# RL6955_IP_SVD register map
Vendor: Realtek
Registers are 32-bit, read-write, reset 0x0 unless marked. A register's access mark holds for its fields unless they carry their own. Offsets are from the block's base; [hi:lo] are bit positions; lines under a group give offsets from that group; {n}, {i} and the like mark numbered series.

## WMAC_PAGE17
Base 0x40000000
0x1700 REG_TWT_BC_ID
  [31:0] BC_TWT_ID — twt id bitmap, each bit corresponding to a ID value, only latch the report of valid twt id
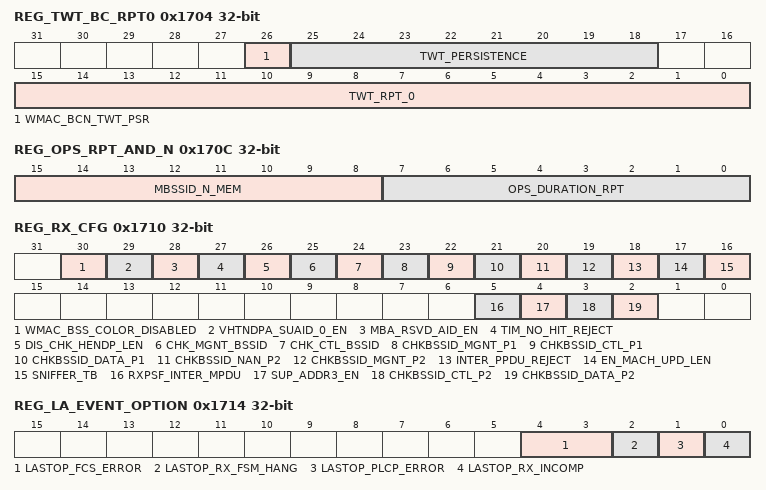
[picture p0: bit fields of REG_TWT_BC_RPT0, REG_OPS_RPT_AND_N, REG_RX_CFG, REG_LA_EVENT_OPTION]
0x1704 REG_TWT_BC_RPT0
  [26] WMAC_BCN_TWT_PSR — when set, enable beacon twt broadcast ie parser
  [25:18] TWT_PERSISTENCE — persistence value, if persistence value in TWT IE is smaller than the reg value, will latch the twt id report
  [15:0] TWT_RPT_0 — specified twt id report
0x1708 REG_TWT_BC_RPT1
  [15:0] TWT_RPT_1 — specified twt id report
0x170C REG_OPS_RPT_AND_N
  [15:8] MBSSID_N_MEM — multi-bssid n value
  [7:0] OPS_DURATION_RPT — ops frame duration field report
0x1710 REG_RX_CFG — rx configure register
  [30] WMAC_BSS_COLOR_DISABLED — sw should set this bit when rx beacon from associated AP
  [29] VHTNDPA_SUAID_0_EN — when set, ndpa that sta info use 0 as aid will check as fit when rx vht/he ndpa
  [28] MBA_RSVD_AID_EN — when set, accept multi-sta ba tha use rsvd aid: 2045 in aid_tid_info as response, used in pre assocaition
  [27] TIM_NO_HIT_REJECT — when set, reject tim no hit beacon
  [26] DIS_CHK_HENDP_LEN — disable check HE NDP lsig length value
  [25] CHK_MGNT_BSSID — enable check port0 management frame bssid
  [24] CHK_CTL_BSSID — enable check port0 control packet bssid,except ack and cts
  [23] CHKBSSID_MGNT_P1 — enable check port1 management frame bssid
  [22] CHKBSSID_CTL_P1 — enable check port1 control frame bssid
  [21] CHKBSSID_DATA_P1 — enable check port1 data frame bssid
  [20] CHKBSSID_NAN_P2 — enable check port2 bssid
  [19] CHKBSSID_MGNT_P2 — when relay mode, enable check port2 management frame bssid
  [18] INTER_PPDU_REJECT — enable reject inter ppdu
  [17] EN_MACH_UPD_LEN — enable macrx_pktfifo_ctl update mpdu length in MACHDR_CHK state
  [16] SNIFFER_TB — enable to receive TB PPDU for debug mode
  [5] RXPSF_INTER_MPDU — enable invalid packet check for inter ppdu, inter ppdu valid when plcp and mac header are inter bss
  [4] SUP_ADDR3_EN — when set, enable check supper address3
  [3] CHKBSSID_CTL_P2 — when relay mode, enable check port2 control frame bssid
  [2] CHKBSSID_DATA_P2 — when relay mode, enable check port2 data frame bssid
0x1714 REG_LA_EVENT_OPTION
  [4:3] LASTOP_FCS_ERROR — stop LA record when continue fcs error>= threshold 0:disable;1:4; 2:8;3:12
  [2] LASTOP_RX_FSM_HANG — stop LA record when RX FSM timeout
  [1] LASTOP_PLCP_ERROR — stop LA record when RX plcp error occur, include length error, parity error or crc8 error
  [0] LASTOP_RX_INCOMP — stop LA record when RX content is incompleted, include PLCP or PSDU are incompleted
0x1718 REG_AID — aid register
  [10:0] AID11 — specified the aid of the sta that mactx response using all ack
0x171C REG_TRAN_BSSID0_L — trasmitted bssid register0_l
  [31:0] WMAC_TRANSBSSID0_L — lower 32 bits of transmitted bssid0
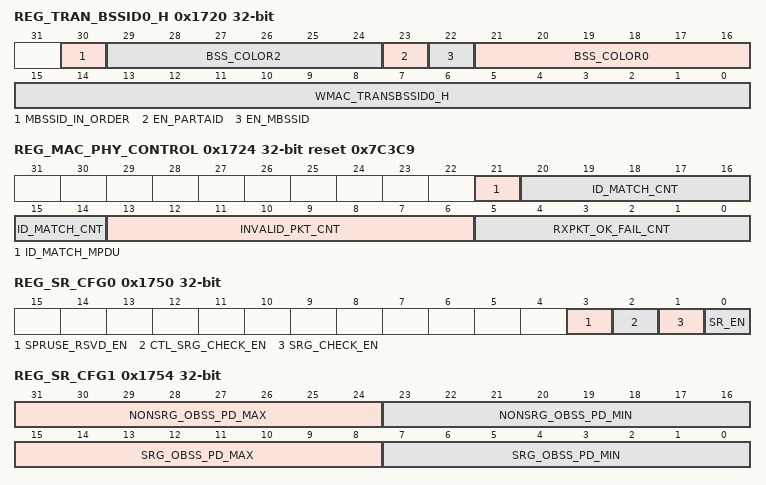
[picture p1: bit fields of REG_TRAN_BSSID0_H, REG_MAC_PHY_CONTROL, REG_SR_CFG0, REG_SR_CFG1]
0x1720 REG_TRAN_BSSID0_H — trasmitted bssid register0_h
  [30] MBSSID_IN_ORDER — transbssid direct mask, not change order
  [29:24] BSS_COLOR2 — bss color of current BSS of port1
  [23] EN_PARTAID — enable inter ppdu decision according to partial aid for VHT ppdu
  [22] EN_MBSSID — enable multibssid function for transmitted bssid compare
  [21:16] BSS_COLOR0 — bss color of current BSS of port0
  [15:0] WMAC_TRANSBSSID0_H — higher 16 bits of transmitted bssid0
0x1724 REG_MAC_PHY_CONTROL reset 0x7C3C9
  [21] ID_MATCH_MPDU — when set, per mpdu will trigger rx_id_match, else per ppdu trigger
  [20:14] ID_MATCH_CNT — rx macid match pulse counter, unit is mac clock
  [13:6] INVALID_PKT_CNT — invalid packet pulse counter, unit is mac clock
  [5:0] RXPKT_OK_FAIL_CNT — rxpkt ok or fail pulse counter, unit is mac clock
0x172C REG_GID_POS_EN_l — VHT group id position enable register
  [31:0] GID_POSITION_EN_L — VHT group id position enable
{0x1730+4i} REG_GID_POS{i} (i=0..3) — VHT group id position{i} register
  [31:0] GID_POSITION{i} — VHT group id position{i}
0x1740 REG_BSSCOLOR_BITMAP_L — bss color bitmap register_l
  [31:0] BSSCOLOR_BITMAP_L — low 32bits bss color bitmap
0x1744 REG_BSSCOLOR_BITMAP_H — bss color bitmap register_h
  [31:0] BSSCOLOR_BITMAP_H — high 32bits bss color bitmap
0x1748 REG_PBSSID_BITMAP_L — partial bssid bitmap register_l
  [31:0] PARTIAL_BSSID_BITMAP_L — low 32bits partial bssid bitmap
0x174C REG_PBSSID_BITMAP_H — partial bssid bitmap register_h
  [31:0] PARTIAL_BSSID_BITMAP_H — high 32bits partial bssid bitmap
0x1750 REG_SR_CFG0 — spatial reuse configure register0
  [3] SPRUSE_RSVD_EN — enable spatia reuse when plcp header spratial reuse field vaule smaller than 14 or value is 15 and is srg ppdu
  [2] CTL_SRG_CHECK_EN — enable control packet srg ppdu check
  [1] SRG_CHECK_EN — enable srg ppdu check
  [0] SR_EN — enable spatial reuse function
0x1754 REG_SR_CFG1 — spatial reuse configure register1
  [31:24] NONSRG_OBSS_PD_MAX — the maximum value of non_SRG OBSS_PD
  [23:16] NONSRG_OBSS_PD_MIN — the minimum value of non_SRG OBSS_PD
  [15:8] SRG_OBSS_PD_MAX — the maximum value of OBSS_PD
  [7:0] SRG_OBSS_PD_MIN — the minimum value of OBSS_PD
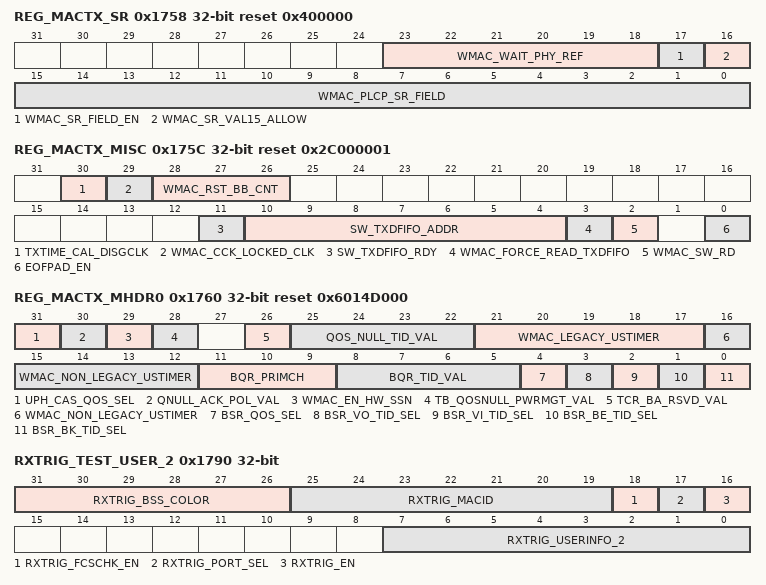
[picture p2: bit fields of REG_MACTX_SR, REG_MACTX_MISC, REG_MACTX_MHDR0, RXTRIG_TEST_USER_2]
0x1758 REG_MACTX_SR reset 0x400000 — SR field configure
  [23:18] WMAC_WAIT_PHY_REF — mactx hang handle,wait phytxon timeout
  [17] WMAC_SR_FIELD_EN — enable sr field reg cfg
  [16] WMAC_SR_VAL15_ALLOW — sr field can be the value 15
  [15:0] WMAC_PLCP_SR_FIELD — value of SR field
0x175C REG_MACTX_MISC reset 0x2C000001 — misc ctrl cfg
  [30] TXTIME_CAL_DISGCLK — disable the clock gating of the txtime compute module
  [29] WMAC_CCK_LOCKED_CLK — indicate that the transmit freuqency and symbol clocks are derived from the same oscilator
  [28:26] WMAC_RST_BB_CNT — macclk cycle number of wmac_rst_bb signal
  [11] SW_TXDFIFO_RDY — sw read txd fifo ready
  [10:4] SW_TXDFIFO_ADDR — sw read txd fifo address,[6:1] is address, [0] : 0 read low 32bit; 1 read high 32bit;
  [3] WMAC_FORCE_READ_TXDFIFO — during tx procedure, force read txd fifo, which is only use at the situation when bb is hang.
  [2] WMAC_SW_RD — eanble sw read txdfifo
  [0] EOFPAD_EN — enable eof pad operation at the end of mpdu
0x1760 REG_MACTX_MHDR0 reset 0x6014D000 — MAC header configure
  [31] UPH_CAS_QOS_SEL — HTC field UPH+CAS format enable,only work in tb_ppdu
  [30] QNULL_ACK_POL_VAL — ack policy bit of tb qos null
  [29] WMAC_EN_HW_SSN — enable the hw ssn for qos null frame
  [28] TB_QOSNULL_PWRMGT_VAL — the power bit in tb qos null, used during twt operation
  [26] TCR_BA_RSVD_VAL — multi-sta BA bactl rsvd filed value
  [25:22] QOS_NULL_TID_VAL — tid value of qos null
  [21:17] WMAC_LEGACY_USTIMER — timer cnt before bb fetch txd for ofdm, for underflow setting
  [16:12] WMAC_NON_LEGACY_USTIMER — timer cnt before bb fetch txd for he/vht/ht/cck, for underflow setting
  [11:9] BQR_PRIMCH — shift bqr bitmap to the allocated primary 20M channel
  [8:5] BQR_TID_VAL — bandwidth query report TID value
  [4] BSR_QOS_SEL — HTC field BSR format enable,only work in tb_ppdu
  [3] BSR_VO_TID_SEL — 1: tid 7; 0: tid 6;
  [2] BSR_VI_TID_SEL — 1: tid 5; 0: tid 4;
  [1] BSR_BE_TID_SEL — 1: tid 2; 0: tid 1;
  [0] BSR_BK_TID_SEL — 1: tid 3; 0: tid 0;
0x1768 REG_MACTX_TXD_FIFO ro — fifo do
  [31:0] SW_TXDFIFO_DOUT — sw read rxd_out
0x1780 RXTRIG_TEST_COMM_0
  [31:0] RXTRIG_COMMON_0 — low 32bit of comm field in trigger frame of test mode
0x1784 RXTRIG_TEST_COMM_1
  [31:0] RXTRIG_COMMON_1 — high32bit of comm field in trigger frame of test mode
0x1788 RXTRIG_TEST_USER_0
  [31:0] RXTRIG_USERINFO_0 — low 32bit of user field in trigger frame of test mode
0x178C RXTRIG_TEST_USER_1
  [31:0] RXTRIG_USERINFO_1 — high 32bit of user field in trigger frame of test mode
0x1790 RXTRIG_TEST_USER_2 access per field
  [31:26] RXTRIG_BSS_COLOR rw
  [25:19] RXTRIG_MACID rw — macid
  [18] RXTRIG_FCSCHK_EN rw — 1:enable fcs check
  [17] RXTRIG_PORT_SEL rw — port sel
  [16] RXTRIG_EN wo — enable rx trigger test mode
  [7:0] RXTRIG_USERINFO_2 rw — L
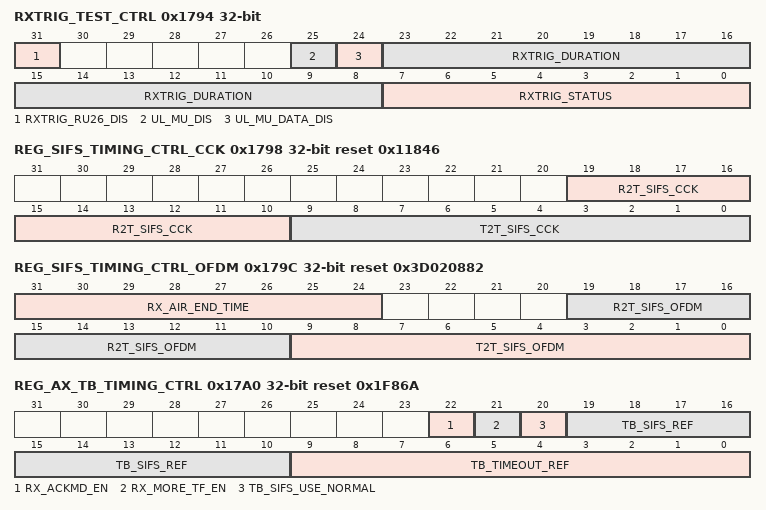
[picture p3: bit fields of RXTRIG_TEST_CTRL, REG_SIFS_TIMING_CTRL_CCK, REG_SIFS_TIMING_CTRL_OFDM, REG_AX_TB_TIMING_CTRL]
0x1794 RXTRIG_TEST_CTRL access per field
  [31] RXTRIG_RU26_DIS rw — disable response to trigger frame when ru allocation addressed to me is 26-tone
  [25] UL_MU_DIS rw — Disable to respond UL response triggered by any trigger frame. Per port config.
  [24] UL_MU_DATA_DIS rw — Disable to respond UL data triggered by basic trigger frame. Per port config. (BA/ACK/BSR/BQR are still allowed to Tx)
  [23:8] RXTRIG_DURATION rw — duration of trigger frame
  [7:0] RXTRIG_STATUS ro — [7:4]:trig_cntr [3:0]:ctl_state
0x1798 REG_SIFS_TIMING_CTRL_CCK reset 0x11846
  [19:10] R2T_SIFS_CCK — This register sets the SIFS time required for any immediate response for example Data-Ack. It is in unit of 100ns.(default:7.5us)
  [9:0] T2T_SIFS_CCK — This register sets the SIFS time required for consecutive TX events for example CTS-Data, or broadcast bursting. It is in unit of 100ns.(default:7.5us)
0x179C REG_SIFS_TIMING_CTRL_OFDM reset 0x3D020882
  [31:24] RX_AIR_END_TIME — This register sets the time from cca fall to 6us. It is in unit of 100ns.(default:6us)
  [19:10] R2T_SIFS_OFDM — This register sets the SIFS time required for any immediate response for example Data-Ack. It is in unit of 100ns.(default:12.6us)
  [9:0] T2T_SIFS_OFDM — This register sets the SIFS time required for consecutive TX events for example CTS-Data, or broadcast bursting. It is in unit of 100ns.(default:13us)
0x17A0 REG_AX_TB_TIMING_CTRL reset 0x1F86A
  [22] RX_ACKMD_EN — receive ack frame will generate interrupt of ack_more_data=0/1
  [21] RX_MORE_TF_EN — receive trigger frame within my bssid but not addressed to me will generate interrupt of more_tf=0/1
  [20] TB_SIFS_USE_NORMAL — 1:choose 0x179c sifs when rx trigger 0:choose 0x17A0[19:10] sifs when rx trigger
  [19:10] TB_SIFS_REF — This register sets the for sifs time between cca falling edge of trigger frame and mactx_enable rising edge.It is in unit of 100ns.(default:12.6us)
  [9:0] TB_TIMEOUT_REF — This register sets the max time for tb data aggragation, It is in unit of 100ns.(default:12us)
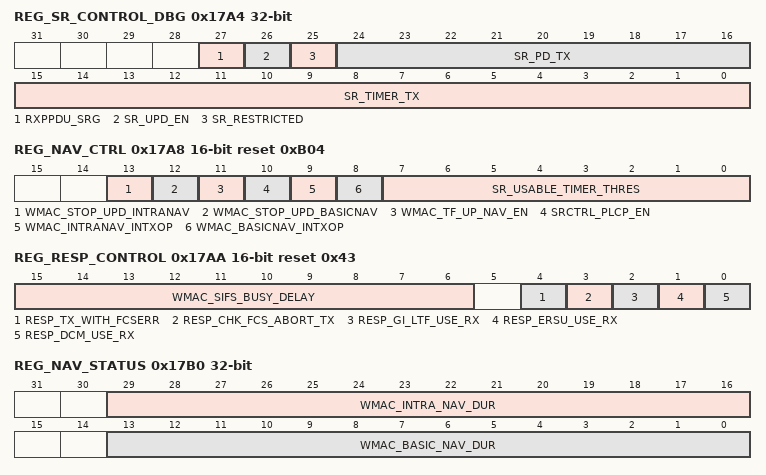
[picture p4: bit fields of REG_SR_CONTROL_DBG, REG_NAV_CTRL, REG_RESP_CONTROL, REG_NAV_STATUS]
0x17A4 REG_SR_CONTROL_DBG ro
  [27] RXPPDU_SRG — the received pkt is an srg ppdu
  [26] SR_UPD_EN — the received pkt is allowed to update basic nav
  [25] SR_RESTRICTED — the spatial reuse type is restricted
  [24:16] SR_PD_TX — the value of received power level minus obss_pd_min
  [15:0] SR_TIMER_TX — time can be used for spatial reuse
0x17A8 REG_NAV_CTRL 16-bit reset 0xB04
  [13] WMAC_STOP_UPD_INTRANAV — disable updating intra nav
  [12] WMAC_STOP_UPD_BASICNAV — disable updating basic nav
  [11] WMAC_TF_UP_NAV_EN — 1:enable updating intra nav when receiving trigger frame
  [10] SRCTRL_PLCP_EN — 1:use txop_dur as sr_tx_timer
  [9] WMAC_INTRANAV_INTXOP — enable updating intra nav in my txop
  [8] WMAC_BASICNAV_INTXOP — enable updating basic nav in my txop
  [7:0] SR_USABLE_TIMER_THRES — If received pkt can operate spatial reuse,the min threshold for sr_timer_tx. unit:256us(default:1024us)
0x17AA REG_RESP_CONTROL 16-bit reset 0x43
  [15:6] WMAC_SIFS_BUSY_DELAY — start to check channel status after a period of delay start from edcca falling edge,unit:100ns
  [4] RESP_TX_WITH_FCSERR — 1:if resp_chk_fcs is low and mactx starts to generate mpdu,will tx response with wrong crc32
  [3] RESP_CHK_FCS_ABORT_TX — 1:if resp_chk_fcs is low when sifs reach,will not respond to the received packet
  [2] RESP_GI_LTF_USE_RX — 1:will use gi ltf type in rxpkt
  [1] RESP_ERSU_USE_RX — enable response tx with ersu when rx ersu
  [0] RESP_DCM_USE_RX — enable response tx with dcm when rx dcm
0x17B0 REG_NAV_STATUS ro
  [29:16] WMAC_INTRA_NAV_DUR — intra_nav
  [13:0] WMAC_BASIC_NAV_DUR — basic_nav
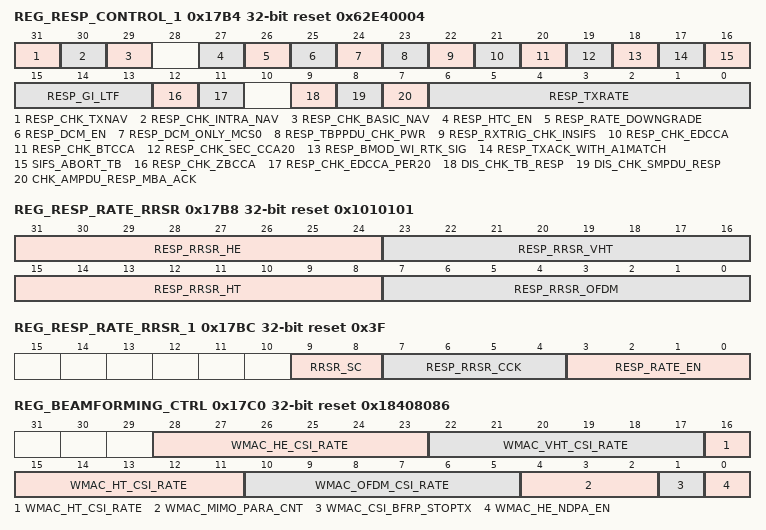
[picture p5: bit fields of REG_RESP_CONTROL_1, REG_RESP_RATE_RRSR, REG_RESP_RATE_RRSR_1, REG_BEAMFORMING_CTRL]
0x17B4 REG_RESP_CONTROL_1 reset 0x62E40004
  [31] RESP_CHK_TXNAV — check txnav when need to response
  [30] RESP_CHK_INTRA_NAV — check intra nav when need to response
  [29] RESP_CHK_BASIC_NAV — check basic nav when need to response
  [27] RESP_HTC_EN — enable appending htc when need to response
  [26] RESP_RATE_DOWNGRADE — enable downgrade response rate from HE to VHT, VHT to HT, HE to HT when need to response
  [25] RESP_DCM_EN — enable using dcm need to response
  [24] RESP_DCM_ONLY_MCS0 — limit response rate to MCS0 when response tx with HE DCM packet
  [23] RESP_TBPPDU_CHK_PWR — check tb ppdu tx power when rx trigger, if txpwr_ctrl send signal of abort,will not reply with tb ppdu
  [22] RESP_RXTRIG_CHK_INSIFS — check whether channel is idle during sifs, if csreq=1 in trigger frame, will not reply with tb ppdu
  [21] RESP_CHK_EDCCA — check edcca when response
  [20] RESP_CHK_BTCCA — check btcca when response
  [19] RESP_CHK_SEC_CCA20 — check sec 20 cca when response
  [18] RESP_BMOD_WI_RTK_SIG — mac will tx response with b mode special preamble when receiving b mode with special preamble
  [17] RESP_TXACK_WITH_A1MATCH — check if rx a1=r_macid0/1 with all bits matched
  [16] SIFS_ABORT_TB — abort ptcl generate tb cmd when sifs reach
  [15:13] RESP_GI_LTF — 5:1x+0.8 4:1x+1.6 3:2x+0.8 2:2x+1.6 1:4x+0.8 0:4x+3.2 not support 1x+1.6 when response
  [12] RESP_CHK_ZBCCA — check zigbee cca when response
  [11] RESP_CHK_EDCCA_PER20 — check edcca_per20_bitmap_sifs[0] when tx response
  [9] DIS_CHK_TB_RESP — if tx tb and receive pgack ,consider as tx ok if this option is enabled
  [8] DIS_CHK_SMPDU_RESP — if tx smpdu and receive ack or mba,consider as tx ok if this option is enabled
  [7] CHK_AMPDU_RESP_MBA_ACK — if tx ampdu or tb data and receive mba_ack, consider as tx ok if this option is enabled
  [6:0] RESP_TXRATE — tx rate use to decide response rate
0x17B8 REG_RESP_RATE_RRSR reset 0x1010101
  [31:24] RESP_RRSR_HE — Data Rate Control Table Register BitMap to indicate the response/protection/expected_response rate to use in this BSS. All management and control response frames should obey the rates set in the bitmap. Each bit is mapped as the following: HE 1SS MCS0~MCS7 Response rate must be less than or equal to the rate of the initiating frame. If none of the bits are set, no response is generated by Rtl8712. If both the legacy rates and HT rates are defined as Basic Rates, fill in only the legacy portion of the bitmap. If only HT rates are defined as Basic Rates, fill in both the legacy and HT portion of the bitmap.
  [23:16] RESP_RRSR_VHT — VHT 1SS MCS0~MCS7
  [15:8] RESP_RRSR_HT — HT 1SS MCS0~MCS7
  [7:0] RESP_RRSR_OFDM — {6M, 9M, 12M, 18M, 24M, 36M, 48M, 54M}
0x17BC REG_RESP_RATE_RRSR_1 reset 0x3F
  [9:8] RRSR_SC — Response frame sub-channel configuration. Response frames (CTS, ACK, BA) are transmitted in the following condition. 00: Primary 20Mhz BW(0x483[3:0] = 0x8AC[5:2]). 01: Follow Rx packet BW mode. 10: Duplicate mode.
  [7:4] RESP_RRSR_CCK — {1M, 2M, 5.5M, 11M }
  [3:0] RESP_RATE_EN — [0]:enable respnse rate of CCK and OFDM [1]:enable respnse rate of HT [2]:enable respnse rate of VHT [3]:enable respnse rate of HE
0x17C0 REG_BEAMFORMING_CTRL reset 0x18408086
  [28:23] WMAC_HE_CSI_RATE — HE CSI init rate(HE mode+ MCS)
  [22:17] WMAC_VHT_CSI_RATE — VHT CSI init rate(VHT mode + MCS)
  [16:11] WMAC_HT_CSI_RATE — HT CSI init rate(HT mode + MCS)
  [10:5] WMAC_OFDM_CSI_RATE — ODFM CSI INIT RATE
  [4:2] WMAC_MIMO_PARA_CNT — width of mimo_para_en,deafult:1(mac clk:20M,pluse width:100ns)
  [1] WMAC_CSI_BFRP_STOPTX — stop tx when rx ndpa/ndp and wait for bfrp poll frame
  [0] WMAC_HE_NDPA_EN — Set to 1, MAC would inform BB of preparing to receive NDP if the received NDPA is valid.
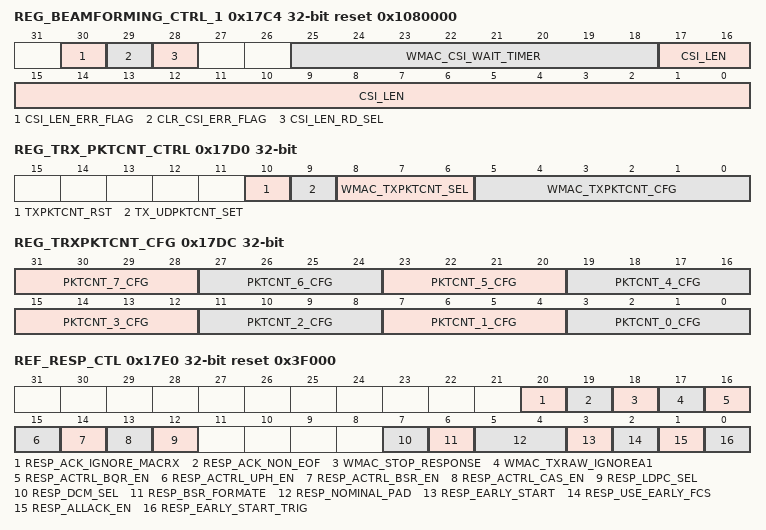
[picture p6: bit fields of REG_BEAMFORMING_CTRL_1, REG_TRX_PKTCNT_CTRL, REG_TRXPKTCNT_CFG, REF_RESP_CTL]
0x17C4 REG_BEAMFORMING_CTRL_1 access per field reset 0x1080000
  [30] CSI_LEN_ERR_FLAG ro — CSI length error
  [29] CLR_CSI_ERR_FLAG wo — clear tb csi_length error flag
  [28] CSI_LEN_RD_SEL rw — 0:read csi rpt length form bb 1:read csi rpt length form mac
  [25:18] WMAC_CSI_WAIT_TIMER rw — set this timer after receiving BFRP or VHT/HE NDPA not solicit a CSI rpt frmae frame me,and should be cleared when receiving a BFRP addressed to me and tx CSI successfully. unit:256us,defult 16ms
  [17:0] CSI_LEN ro — csi rpt length choosed by 0x17c4[28]
0x17C8 REG_LBK_CFG reset 0x12
  [6:0] MACLBK_RDY_PERIOD — tdrdy/rdrdy interval count
0x17CC REG_GID_POS_EN_H — VHT group id position enable register
  [31:0] GID_POSITION_EN_H — VHT group id position enable
0x17D0 REG_TRX_PKTCNT_CTRL
  [10] TXPKTCNT_RST — Reset tx packet counter
  [9] TX_UDPKTCNT_SET — loading user define packet counter cfg
  [8:6] WMAC_TXPKTCNT_SEL — Tx packet counter selection 3'd0: counter 0 3'd1: counter 1 3'd2: counter 2 3'd3: counter 3 3'd4: counter 4 3'd5: counter 5 3'd6: counter 6 3'd7: counter 7
  [5:0] WMAC_TXPKTCNT_CFG — User define [5:2]:subtype [1:0]:type
0x17D4 REG_TRX_PKTCNT ro
  [24:0] RO_WMAC_TXPKTCNT_RPT — Tx packet counter
0x17DC REG_TRXPKTCNT_CFG
  [31:28] PKTCNT_7_CFG — Packet counter 7 type config. If configured , counter 7 will count only for the selected type. bit[31] = 0: Tx, bit[31]=1: Rx. 4'b0000: Tx User Define MPDU 4'b0001: Tx HE SU MPDU 4'b0010: Tx HE SU PPDU 4'b0011: Tx HE TB MPDU 4'b0100: Tx HE TB PPDU 4'b1000: Rx packet full drop 4'b1001: Rx drop packet 4'b1010: Rx invalid packet 4'b1011: Rx total OK 4'b1100: Rx total Fail 4'b1101: Rx User Define OK 4'b1110: Rx CCK OK 4'b1111: Rx CCK Fail
  [27:24] PKTCNT_6_CFG — Packet counter 6 type config. If configured , counter 6 will count only for the selected type. bit[27] = 0: Tx, bit[27]=1: Rx. 4'b0000: Tx Total MPDU 4'b0001: Tx Total PPDU 4'b0010: Tx HT MPDU 4'b0011: Tx HT PPDU 4'b0100: Tx VHT SU MPDU 4'b0101: Tx VHT SU PPDU 4'b1000: Rx HE MU OK 4'b1001: Rx HE MU Fail 4'b1010: Rx HE MU PPDU 4'b1011: Rx packet full drop 4'b1100: Rx drop packet 4'b1101: Rx invalid packet 4'b1110: Rx total OK 4'b1111: Rx total Fail
  [23:20] PKTCNT_5_CFG — Packet counter 5 type config. If configured , counter 5 will count only for the selected type. bit[23] = 0: Tx, bit[23]=1: Rx. 4'b0000: Tx HE TB MPDU 4'b0001: Tx HE TB PPDU 4'b0010: Tx Total MPDU 4'b0011: Tx Total PPDU 4'b1000: Rx HE SU OK 4'b1001: Rx HE SU Fail 4'b1010: Rx HE SU PPDU 4'b1011: Rx HE SU False Alarm 4'b1100: Rx HE MU OK 4'b1101: Rx HE MU Fail 4'b1110: Rx HE MU PPDU 4'b1111: Rx HE MU False Alarm
  [19:16] PKTCNT_4_CFG — Packet counter 4 type config. If configured , counter 4 will count only for the selected type. bit[19] = 0: Tx, bit[19]=1: Rx. 4'b0000: Tx HE SU MPDU 4'b0001: Tx HE SU PPDU 4'b0010: Tx HE TB MPDU 4'b0011: Tx HE TB PPDU 4'b1000: Rx VHT MU OK 4'b1001: Rx VHT MU Fail 4'b1010: Rx VHT MU PPDU 4'b1011: Rx VHT MU False Alarm 4'b1100: Rx HE SU OK 4'b1101: Rx HE SU Fail 4'b1110: Rx HE SU PPDU 4'b1111: Rx HE SU False Alarm
  [15:12] PKTCNT_3_CFG — Packet counter 3 type config. If configured , counter 3 will count only for the selected type. bit[15] = 0: Tx, bit[15]=1: Rx. 4'b0000: Tx VHT SU MPDU 4'b0001: Tx VHT SU PPDU 4'b0010: Tx HE SU MPDU 4'b0011: Tx HE SU PPDU 4'b1000: Rx VHT SU OK 4'b1001: Rx VHT SU Fail 4'b1010: Rx VHT SU PPDU 4'b1011: Rx VHT SU False Alarm 4'b1100: Rx VHT MU OK 4'b1101: Rx VHT MU Fail 4'b1110: Rx VHT MU PPDU 4'b1111: Rx VHT MU False Alarm
  [11:8] PKTCNT_2_CFG — Packet counter 2 type config. If configured , counter 2 will count only for the selected type. bit[11] = 0: Tx, bit[11]=1: Rx. 4'b0000: Tx HT MPDU 4'b0001: Tx HT PPDU 4'b0010: Tx VHT SU MPDU 4'b0011: Tx VHT SU PPDU 4'b1000: Rx HT OK 4'b1001: Rx HT Fail 4'b1010: Rx HT PPDU 4'b1011: Rx HT False Alarm 4'b1100: Rx VHT SU OK 4'b1101: Rx VHT SU Fail 4'b1110: Rx VHT SU PPDU 4'B1111: Rx VHT SU False Alarm
  [7:4] PKTCNT_1_CFG — Packet counter 1 type config. If configured , counter 1 will count only for the selected type. bit[7] = 0: Tx, bit[7]=1: Rx. 4'b0000~4'b0111: Tx OFDM PPDU 4'b1000: Rx OFDM OK 4'b1001: Rx OFDM Fail 4'b1010: Rx OFDM False Alarm 4'b1011: Rx HT OK 4'b1100: Rx HT Fail 4'b1101: Rx HT PPDU 4'b1110: Rx HT False Alarm
  [3:0] PKTCNT_0_CFG — Packet counter 0 type config. If configured , counter 0 will count only for the selected type. bit[3] = 0: Tx, bit[3]=1: Rx. 4'b0000~4'b0111: Tx CCK PPDU 4'b1000: Rx CCK OK 4'b1001: Rx CCK Fail 4'b1010: Rx CCK False Alarm 4'b1011: Rx OFDM OK 4'b1100: Rx OFDM Fail 4'b1101: Rx OFDM False Alarm
0x17E0 REF_RESP_CTL reset 0x3F000
  [20] RESP_ACK_IGNORE_MACRX — when set, will response tx regardless of macrx active
  [19] RESP_ACK_NON_EOF — when set, will response tx ack to mgt frame with eof=0 in trigger frame
  [18] WMAC_STOP_RESPONSE — when set, will not resposne tx
  [17] WMAC_TXRAW_IGNOREA1 — when set, will not check rx a1 of packet that is response to txraw
  [16] RESP_ACTRL_BQR_EN — when set, hw would update BQR info to A-CTRL
  [15] RESP_ACTRL_UPH_EN — when set, hw would update UPH info to A-CTRL
  [14] RESP_ACTRL_BSR_EN — when set, hw would update BSR info to A-CTRL
  [13] RESP_ACTRL_CAS_EN — when set, hw would update CAS info to A-CTRL
  [12] RESP_LDPC_SEL — 1: follow ctrl reg 0x668[15]; 0: follow rx pkt, used when control info is not valid
  [7] RESP_DCM_SEL — 1: follow ctrl reg 0x17e0[25]; 0: follow rx pkt, used when control info is not valid
  [6] RESP_BSR_FORMATE — 0: queue size of QOS field us non-he formate; 1: queue size of QOS field us he formate,vaild when
  [5:4] RESP_NOMINAL_PAD — norminal packet padding:0:0us;1:8us;2:16us;Tpe is decided by nominal packet adding and pre-FEC padding factor
  [3] RESP_EARLY_START — when set,response satrt early when responsd to non-trigger frame
  [2] RESP_USE_EARLY_FCS — when set, use rx fifo fcs when response data that use wep/tkip
  [1] RESP_ALLACK_EN — when set, enable tx multi sta ba-all ack as response, used when control info is not valid
  [0] RESP_EARLY_START_TRIG — when set,response satrt early when rx trigger frame except basic trigger
0x17E4 REG_TXPWR_CTL reset 0x1
  [0] TXPWR_FAST_MODE_EN — fast mode enable for txpwr_ctl, tie 1 for AMEBAD2
0x17E8 REG_DUMMY_PAGE17
  [31:0] DUMMY
0x17F0 REG_MASK_LA_TRX_DBG_L
  [31:0] LA_TRX_PATTERN_MASK_L — used for mask for debug port in iqdump
0x17F4 REG_MASK_LA_TRX_DBG_H
  [31:0] LA_TRX_PATTERN_MASK_H — used for mask for debug port in iqdump
0x17F8 REG_REF_LA_TRX_DBG_L
  [31:0] LA_TRX_PATTERN_REF_L — used for mask for debug port in iqdump
0x17FC REG_REF_LA_TRX_DBG_H
  [31:0] LA_TRX_PATTERN_REF_H — used for mask for debug port in iqdump
